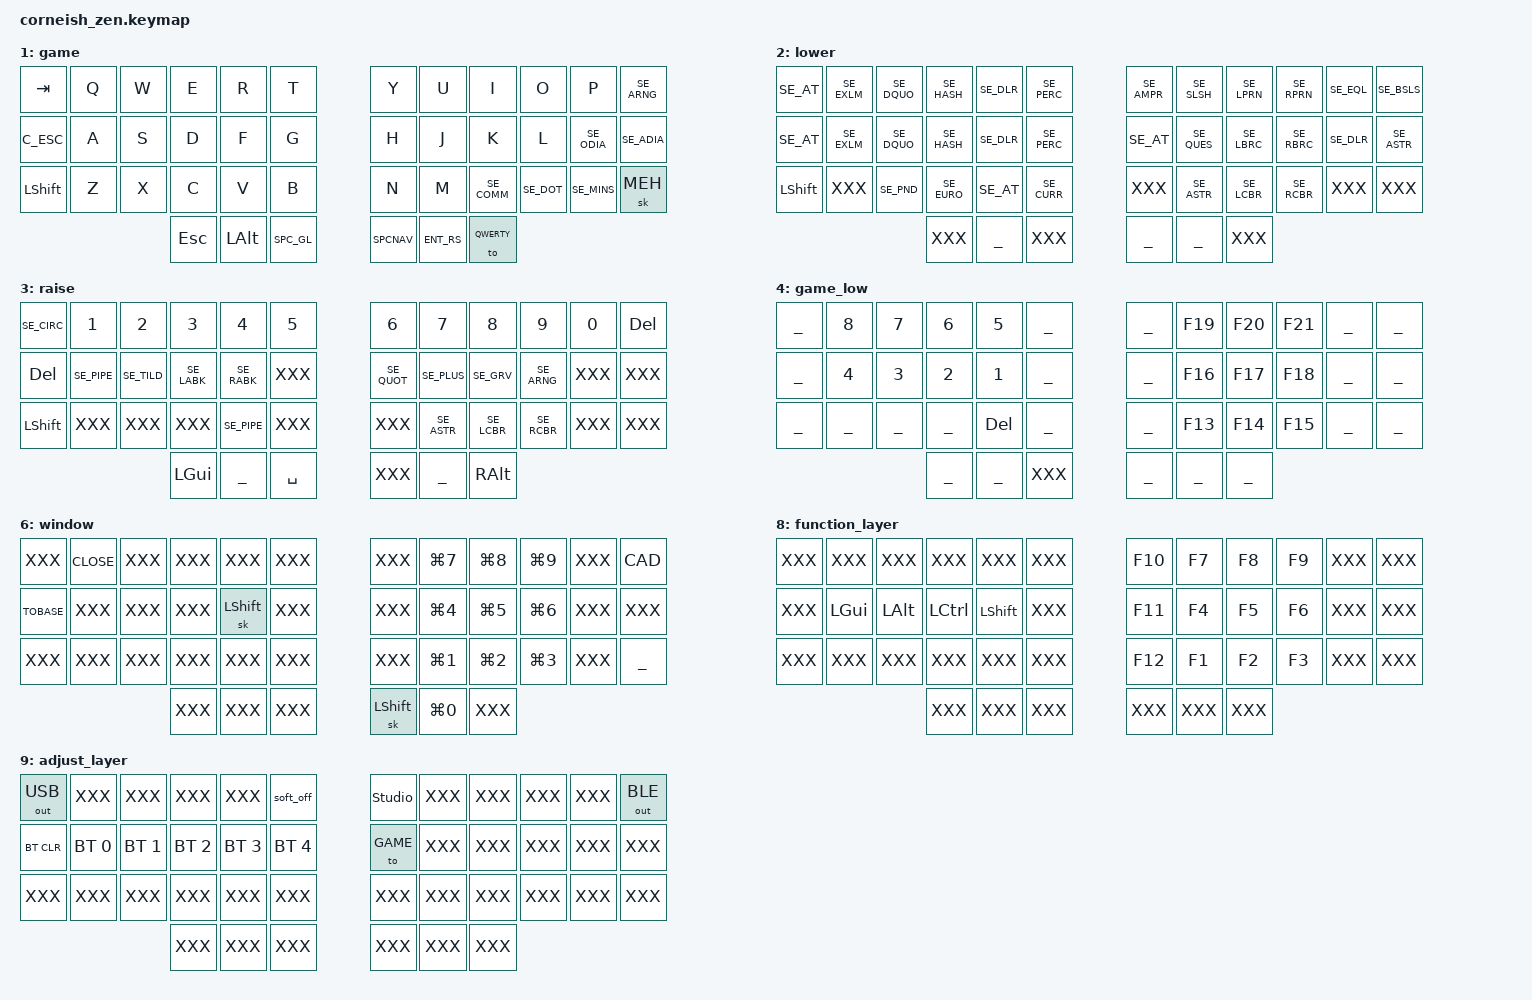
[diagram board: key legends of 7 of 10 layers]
/*
 *
 * Copyright (c) 2021 Darryl deHaan
 * SPDX-License-Identifier: MIT
 *
 */

#include <behaviors.dtsi>
#include <dt-bindings/zmk/keys.h>
#include <dt-bindings/zmk/bt.h>
#include <dt-bindings/zmk/outputs.h>

#include "zmk-helpers/helper.h"
#include "zmk-helpers/key-labels/42.h"
#include "../shared/swedish.h"
#include "homerow_mods.h"
#include "corneish_zen.h"
#include "../shared/macros.dtsi"
#include "combos.dtsi"

#define QUICK_TAP_MS 175

// tap: sticky-shift | shift + tap/ double-tap: caps-word | hold: shift
ZMK_BEHAVIOR(smart_shft, mod_morph,
    bindings = <&sk LSHFT>, <&caps_word>;
    mods = <(MOD_LSFT)>;
)

// tap: sticky shift | double tap: capsword
ZMK_BEHAVIOR(smart_wm, tap_dance,
    tapping-term-ms = <QUICK_TAP_MS>;
    bindings = <&sl WM>, <&to WM>;
)

&caps_word {
    continue-list = <SE_UNDS SE_MINS BACKSPACE>;
    /delete-property/ ignore-modifiers;
};

&sk {  // sticky-key config
    release-after-ms = <900>;  // release after 0.6s
    quick-release;             // no double capitalization when rolling keys
};

&sl {  // sticky-layer config
    ignore-modifiers;          // allow chording sticky mods & layers
};

&lt {  // layer-tap config
    flavor = "balanced";
    tapping-term-ms = <200>;
    quick-tap-ms = <QUICK_TAP_MS>;
};

&soft_off {
    hold-time-ms = <3000>; // Hold for 3s to turn off
};

ZMK_CONDITIONAL_LAYER(adj_layer, LOWER RAISE, ADJUST)

// clang-format off
ZMK_LAYER(qwerty,
//╭─────────────┬─────────────┬─────────────┬─────────────┬─────────────┬─────────────╮  ╭─────────────┬─────────────┬─────────────┬─────────────┬─────────────┬─────────────╮
    TABFNC        &kp Q         &kp W         &kp E         &kp R         &kp T            &kp Y         &kp U         &kp I         &kp O         &kp P         &kp SE_ARNG
//├─────────────┼─────────────┼─────────────┼─────────────┼─────────────┼─────────────┤  ├─────────────┼─────────────┼─────────────┼─────────────┼─────────────┼─────────────┤
    C_ESC         HRM_A         HRM_S         HRM_D         HRM_F         &kp G            &kp H         HRM_J         HRM_K         HRM_L         HRM_OE        &kp SE_ADIA
//├─────────────┼─────────────┼─────────────┼─────────────┼─────────────┼─────────────┤  ├─────────────┼─────────────┼─────────────┼─────────────┼─────────────┼─────────────┤
    &smart_shft   &kp Z         &kp X         &kp C         &kp V         &kp B            &kp N         &kp M         &kp SE_COMM   &kp SE_DOT    &kp SE_MINS   &smart_wm
//╰─────────────┴─────────────┴─────────────┴─────────────┼─────────────┼─────────────┤  ├─────────────┼─────────────┼─────────────┼─────────────┴─────────────┴─────────────╯
                                              &smart_shft   BS_LOW        TABNUM           SPCNAV        ENT_RS        &sk MEH
//                                          ╰─────────────┴─────────────┴─────────────╯  ╰─────────────┴─────────────┴─────────────╯
)

ZMK_LAYER(game,
//╭─────────────┬─────────────┬─────────────┬─────────────┬─────────────┬─────────────╮  ╭─────────────┬─────────────┬─────────────┬─────────────┬─────────────┬─────────────╮
    &kp TAB       &kp Q         &kp W         &kp E         &kp R         &kp T            &kp Y         &kp U         &kp I         &kp O         &kp P         &kp SE_ARNG
//├─────────────┼─────────────┼─────────────┼─────────────┼─────────────┼─────────────┤  ├─────────────┼─────────────┼─────────────┼─────────────┼─────────────┼─────────────┤
    C_ESC         &kp A         &kp S         &kp D         &kp F         &kp G            &kp H         &kp J         &kp K         &kp L         &kp SE_ODIA   &kp SE_ADIA
//├─────────────┼─────────────┼─────────────┼─────────────┼─────────────┼─────────────┤  ├─────────────┼─────────────┼─────────────┼─────────────┼─────────────┼─────────────┤
    &kp LSHFT     &kp Z         &kp X         &kp C         &kp V         &kp B            &kp N         &kp M         &kp SE_COMM   &kp SE_DOT    &kp SE_MINS   &sk MEH
//╰─────────────┴─────────────┴─────────────┴─────────────┼─────────────┼─────────────┤  ├─────────────┼─────────────┼─────────────┼─────────────┴─────────────┴─────────────╯
                                              &kp ESC       &kp LALT      SPC_GL           SPCNAV        ENT_RS        &to QWERTY
//                                          ╰─────────────┴─────────────┴─────────────╯  ╰─────────────┴─────────────┴─────────────╯
)

ZMK_LAYER(lower,
//╭─────────────┬─────────────┬─────────────┬─────────────┬─────────────┬─────────────╮  ╭─────────────┬─────────────┬─────────────┬─────────────┬─────────────┬─────────────╮
    &kp SE_AT     &kp SE_EXLM   &kp SE_DQUO   &kp SE_HASH   &kp SE_DLR    &kp SE_PERC      &kp SE_AMPR   &kp SE_SLSH   &kp SE_LPRN   &kp SE_RPRN   &kp SE_EQL    &kp SE_BSLS
//├─────────────┼─────────────┼─────────────┼─────────────┼─────────────┼─────────────┤  ├─────────────┼─────────────┼─────────────┼─────────────┼─────────────┼─────────────┤
    &kp SE_AT     &kp SE_EXLM   &kp SE_DQUO   &kp SE_HASH   &kp SE_DLR    &kp SE_PERC      &kp SE_AT     &kp SE_QUES   &kp SE_LBRC   &kp SE_RBRC   &kp SE_DLR    &kp SE_ASTR
//├─────────────┼─────────────┼─────────────┼─────────────┼─────────────┼─────────────┤  ├─────────────┼─────────────┼─────────────┼─────────────┼─────────────┼─────────────┤
    &kp LSHFT     XXX           &kp SE_PND    &kp SE_EURO   &kp SE_AT     &kp SE_CURR      XXX           &kp SE_ASTR   &kp SE_LCBR   &kp SE_RCBR   XXX           XXX
//╰─────────────┴─────────────┴─────────────┴─────────────┼─────────────┼─────────────┤  ├─────────────┼─────────────┼─────────────┼─────────────┴─────────────┴─────────────╯
                                              XXX           ___           XXX              ___           ___           XXX
//                                          ╰─────────────┴─────────────┴─────────────╯  ╰─────────────┴─────────────┴─────────────╯
)

ZMK_LAYER(raise,
//╭─────────────┬─────────────┬─────────────┬─────────────┬─────────────┬─────────────╮  ╭─────────────┬─────────────┬─────────────┬─────────────┬─────────────┬─────────────╮
    &kp SE_CIRC   &kp N1        &kp N2        &kp N3        &kp N4        &kp N5           &kp N6        &kp N7        &kp N8        &kp N9        &kp N0        &kp DEL
//├─────────────┼─────────────┼─────────────┼─────────────┼─────────────┼─────────────┤  ├─────────────┼─────────────┼─────────────┼─────────────┼─────────────┼─────────────┤
    &kp DEL       &kp SE_PIPE   &kp SE_TILD   &kp SE_LABK   &kp SE_RABK   XXX              &kp SE_QUOT   &kp SE_PLUS   &kp SE_GRV    &kp SE_ARNG   XXX           XXX
//├─────────────┼─────────────┼─────────────┼─────────────┼─────────────┼─────────────┤  ├─────────────┼─────────────┼─────────────┼─────────────┼─────────────┼─────────────┤
    &kp LSHFT     XXX           XXX           XXX           &kp SE_PIPE   XXX              XXX           &kp SE_ASTR   &kp SE_LCBR   &kp SE_RCBR   XXX           XXX
//╰─────────────┴─────────────┴─────────────┴─────────────┼─────────────┼─────────────┤  ├─────────────┼─────────────┼─────────────┼─────────────┴─────────────┴─────────────╯
                                              &kp LGUI      ___           &kp SPACE        XXX           ___           &kp RALT
//                                          ╰─────────────┴─────────────┴─────────────╯  ╰─────────────┴─────────────┴─────────────╯
)

ZMK_LAYER(game_low,
//╭─────────────┬─────────────┬─────────────┬─────────────┬─────────────┬─────────────╮  ╭─────────────┬─────────────┬─────────────┬─────────────┬─────────────┬─────────────╮
    ___           &kp N8        &kp N7        &kp N6        &kp N5        ___              ___           &kp F19       &kp F20       &kp F21       ___           ___
//├─────────────┼─────────────┼─────────────┼─────────────┼─────────────┼─────────────┤  ├─────────────┼─────────────┼─────────────┼─────────────┼─────────────┼─────────────┤
    ___           &kp N4        &kp N3        &kp N2        &kp N1        ___              ___           &kp F16       &kp F17       &kp F18       ___           ___
//├─────────────┼─────────────┼─────────────┼─────────────┼─────────────┼─────────────┤  ├─────────────┼─────────────┼─────────────┼─────────────┼─────────────┼─────────────┤
    ___           ___           ___           ___           &kp DEL       ___              ___           &kp F13       &kp F14       &kp F15       ___           ___
//╰─────────────┴─────────────┴─────────────┴─────────────┼─────────────┼─────────────┤  ├─────────────┼─────────────┼─────────────┼─────────────┴─────────────┴─────────────╯
                                              ___           ___           XXX              ___           ___           ___
//                                          ╰─────────────┴─────────────┴─────────────╯  ╰─────────────┴─────────────┴─────────────╯
)

ZMK_LAYER(nav,
//╭─────────────┬─────────────┬─────────────┬─────────────┬─────────────┬─────────────╮  ╭─────────────┬─────────────┬─────────────┬─────────────┬─────────────┬─────────────╮
    XXX           XXX           &kp LGUI      &kp LALT      XXX           &kp PG_UP        YANK          TAB_PREV      &m_forward    TAB_NEXT      PASTE         XXX
//├─────────────┼─────────────┼─────────────┼─────────────┼─────────────┼─────────────┤  ├─────────────┼─────────────┼─────────────┼─────────────┼─────────────┼─────────────┤
    TOBASE        &kp HOME      &kp END       &kp LCTRL     &kp LSHFT     &kp PG_DN        &kp LEFT      &kp DOWN      &kp UP        &kp RIGHT     &kp DEL       XXX
//├─────────────┼─────────────┼─────────────┼─────────────┼─────────────┼─────────────┤  ├─────────────┼─────────────┼─────────────┼─────────────┼─────────────┼─────────────┤
    XXX           XXX           DLINE         COMNT         DUPLIC        XXX              CLeft         YANK          PASTE         CRight        XXX           &kp PSCRN
//╰─────────────┴─────────────┴─────────────┴─────────────┼─────────────┼─────────────┤  ├─────────────┼─────────────┼─────────────┼─────────────┴─────────────┴─────────────╯
                                              XXX           &kp BSPC      &kp TAB          TOBASE        &kp ENTER     XXX
//                                          ╰─────────────┴─────────────┴─────────────╯  ╰─────────────┴─────────────┴─────────────╯
)

ZMK_LAYER(window,
//╭─────────────┬─────────────┬─────────────┬─────────────┬─────────────┬─────────────╮  ╭─────────────┬─────────────┬─────────────┬─────────────┬─────────────┬─────────────╮
    XXX           CLOSE         XXX           XXX           XXX           XXX              XXX           &kp LG(N7)    &kp LG(N8)    &kp LG(N9)    XXX           CAD
//├─────────────┼─────────────┼─────────────┼─────────────┼─────────────┼─────────────┤  ├─────────────┼─────────────┼─────────────┼─────────────┼─────────────┼─────────────┤
    TOBASE        XXX           XXX           XXX           &sk LSHFT     XXX              XXX           &kp LG(N4)    &kp LG(N5)    &kp LG(N6)    XXX           XXX
//├─────────────┼─────────────┼─────────────┼─────────────┼─────────────┼─────────────┤  ├─────────────┼─────────────┼─────────────┼─────────────┼─────────────┼─────────────┤
    XXX           XXX           XXX           XXX           XXX           XXX              XXX           &kp LG(N1)    &kp LG(N2)    &kp LG(N3)    XXX           ___
//╰─────────────┴─────────────┴─────────────┴─────────────┼─────────────┼─────────────┤  ├─────────────┼─────────────┼─────────────┼─────────────┴─────────────┴─────────────╯
                                              XXX           XXX           XXX              &sk LSHFT     &kp LG(N0)    XXX
//                                          ╰─────────────┴─────────────┴─────────────╯  ╰─────────────┴─────────────┴─────────────╯
)

ZMK_LAYER(number,
//╭─────────────┬─────────────┬─────────────┬─────────────┬─────────────┬─────────────╮  ╭─────────────┬─────────────┬─────────────┬─────────────┬─────────────┬─────────────╮
    &kp TAB       XXX           TAB_PREV      &m_back       TAB_NEXT      XXX              &kp KP_DIVIDE &kp N7        &kp N8        &kp N9        &kp KP_MULTIPLY &kp BSPC
//├─────────────┼─────────────┼─────────────┼─────────────┼─────────────┼─────────────┤  ├─────────────┼─────────────┼─────────────┼─────────────┼─────────────┼─────────────┤
    SEL_A         XXX           KUT           YANK          PASTE         NEXT             &kp BSPC      &kp N4        &kp N5        &kp N6        &kp KP_MINUS  XXX
//├─────────────┼─────────────┼─────────────┼─────────────┼─────────────┼─────────────┤  ├─────────────┼─────────────┼─────────────┼─────────────┼─────────────┼─────────────┤
    XXX           XXX           XXX           XXX           XXX           XXX              &kp TAB       &kp N1        &kp N2        &kp N3        &kp KP_PLUS   &caps_word
//╰─────────────┴─────────────┴─────────────┴─────────────┼─────────────┼─────────────┤  ├─────────────┼─────────────┼─────────────┼─────────────┴─────────────┴─────────────╯
                                              XXX           XXX           XXX              &kp SPACE     &kp N0        &kp ENTER
//                                          ╰─────────────┴─────────────┴─────────────╯  ╰─────────────┴─────────────┴─────────────╯
)

ZMK_LAYER(function_layer,
//╭─────────────┬─────────────┬─────────────┬─────────────┬─────────────┬─────────────╮  ╭─────────────┬─────────────┬─────────────┬─────────────┬─────────────┬─────────────╮
    XXX           XXX           XXX           XXX           XXX           XXX              &kp F10       &kp F7        &kp F8        &kp F9        XXX           XXX
//├─────────────┼─────────────┼─────────────┼─────────────┼─────────────┼─────────────┤  ├─────────────┼─────────────┼─────────────┼─────────────┼─────────────┼─────────────┤
    XXX           &kp LGUI      &kp LALT      &kp LCTRL     &kp LSHFT     XXX              &kp F11       &kp F4        &kp F5        &kp F6        XXX           XXX
//├─────────────┼─────────────┼─────────────┼─────────────┼─────────────┼─────────────┤  ├─────────────┼─────────────┼─────────────┼─────────────┼─────────────┼─────────────┤
    XXX           XXX           XXX           XXX           XXX           XXX              &kp F12       &kp F1        &kp F2        &kp F3        XXX           XXX
//╰─────────────┴─────────────┴─────────────┴─────────────┼─────────────┼─────────────┤  ├─────────────┼─────────────┼─────────────┼─────────────┴─────────────┴─────────────╯
                                              XXX           XXX           XXX              XXX           XXX           XXX
//                                          ╰─────────────┴─────────────┴─────────────╯  ╰─────────────┴─────────────┴─────────────╯
)

ZMK_LAYER(adjust_layer,
//╭─────────────┬──────────────┬─────────────┬─────────────┬─────────────┬─────────────╮  ╭─────────────┬─────────────┬─────────────┬─────────────┬─────────────┬─────────────╮
    &out OUT_USB  XXX            XXX           XXX           XXX           &soft_off        &studio_unlock XXX           XXX           XXX           XXX           &out OUT_BLE
//├─────────────┼──────────────┼─────────────┼─────────────┼─────────────┼─────────────┤  ├─────────────┼─────────────┼─────────────┼─────────────┼─────────────┼─────────────┤
    &bt BT_CLR    &bt BT_SEL 0   &bt BT_SEL 1  &bt BT_SEL 2  &bt BT_SEL 3  &bt BT_SEL 4     &to GAME      XXX           XXX           XXX           XXX           XXX
//├─────────────┼──────────────┼─────────────┼─────────────┼─────────────┼─────────────┤  ├─────────────┼─────────────┼─────────────┼─────────────┼─────────────┼─────────────┤
    XXX           XXX            XXX           XXX           XXX           XXX              XXX           XXX           XXX           XXX           XXX           XXX
//╰─────────────┴──────────────┴─────────────┴─────────────┼─────────────┼─────────────┤  ├─────────────┼─────────────┼─────────────┼─────────────┴─────────────┴─────────────╯
                                               XXX           XXX           XXX              XXX           XXX           XXX
//                                           ╰─────────────┴─────────────┴─────────────╯  ╰─────────────┴─────────────┴─────────────╯
)
// clang-format on
